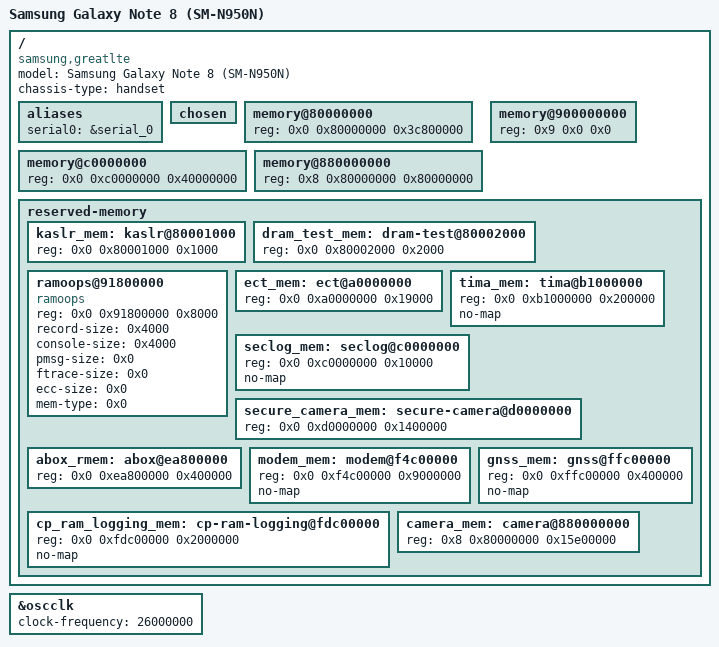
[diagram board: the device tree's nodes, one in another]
// SPDX-License-Identifier: GPL-2.0 OR BSD-3-Clause
/*
 * Samsung Galaxy Note 8 (greatlte, SM-N950N) device tree source
 */

/dts-v1/;

/*
 * Stock: S:arch/arm64/boot/dts/exynos/exynos8895-greatlte-rmem.dtsi:12
 * "/memreserve/ 0xE0000000 0x1900000;", shipped: FDT:3. No user in the
 * stock kernel tree. Owner: the secure-world DRM firmware in cm.bin, which
 * builds a region descriptor {0xe0000000, 0x1900000} for its secure SysMMU
 * page tables and protects it through PPMPU (CM:0x22d2b4-0x22d370, strings
 * CM:0x2306a0 "DRMFW:Invalid page table addr(0x%x)", CM:0x2306c5
 * "DRMFW:PPMPU set fail in SysMMU. ret(%d)"; 4.5, O5 closed).
 * Kept verbatim like stock: memblock_reserve()d, stays in the linear map
 * (A:drivers/of/fdt.c:514-523).
 * It must precede every node, i.e. the #include below: dtc's grammar is
 * "headers memreserves devicetree" (A:scripts/dtc/dtc-parser.y:106-107);
 * same order as A:arch/arm64/boot/dts/airoha/en7581-evb.dts:2-5.
 */
/memreserve/ 0xe0000000 0x1900000;

#include "exynos8895.dtsi"

/ {
	model = "Samsung Galaxy Note 8 (SM-N950N)";	/* FDT:9 "Samsung SM-N950N board based on EXYNOS8895" */
	compatible = "samsung,greatlte", "samsung,exynos8895";
	chassis-type = "handset";

	aliases {
		/*
		 * Stock alias uart0 = &serial_0 (S:arch/arm64/boot/dts/exynos/exynos8895.dtsi:66).
		 * samsung_tty takes the port index from the "serial" alias
		 * (A:drivers/tty/serial/samsung_tty.c:1961), so the debug UART stays
		 * ttySAC0, the name S-Boot passes (" androidboot.sec_atd.tty=/dev/ttySAC0",
		 * SB+0xfacc0). serial_0 itself stays disabled until L1.
		 */
		serial0 = &serial_0;
	};

	/*
	 * S-Boot replaces bootargs wholesale and writes 1-cell (4-byte)
	 * linux,initrd-start/-end = 0x89000000 / 0x89000000 + size into this
	 * node (SB+0xebfb0-0xebfd4 "mov w1, #9; movk w1, #0x5441, lsl #16; cmp w0, w1"
	 * = ATAG_CMDLINE, then setprop "/chosen" "bootargs"; SB+0xec01c-0xec064
	 * "linux,initrd-start"/"-end" as 1-cell values, helper SB+0xebe54 "mov w4, #4").
	 * No bootargs here: it is dead (IK:530; 3.1 step 17). No stdout-path:
	 * S-Boot always passes "console=ram", and of_console_check() ignores
	 * stdout-path whenever console= is on the command line
	 * (A:drivers/of/base.c:2032).
	 */
	chosen {
	};

	/* S:arch/arm64/boot/dts/exynos/exynos8895-greatlte_common.dtsi:27-30, FDT:11126-11129: 968 MiB, ends at the secure hole 0xbc800000 */
	memory@80000000 {
		device_type = "memory";
		reg = <0x0 0x80000000 0x3c800000>;
	};

	/* S:arch/arm64/boot/dts/exynos/exynos8895-greatlte_common.dtsi:32-35, FDT:11131-11134 */
	memory@c0000000 {
		device_type = "memory";
		reg = <0x0 0xc0000000 0x40000000>;
	};

	/* S:arch/arm64/boot/dts/exynos/exynos8895-greatlte_common.dtsi:37-40, FDT:11136-11139 */
	memory@880000000 {
		device_type = "memory";
		reg = <0x8 0x80000000 0x80000000>;
	};

	/*
	 * Filled by S-Boot on 6 GB units: reg = <0x9 0x0 0x80000000>
	 * (SB+0xebff8-0xec00c "cmp w0, #6; b.eq" DRAM==6 test, SB+0xec13c-0xec184
	 * "mov x2, #0x9000000" ... "mov w4, #0xc" setprop).
	 * The node name must be exactly "memory@900000000" (S-Boot looks up that
	 * literal path, SB+0x10e318 "/memory@900000000") and it must carry device_type,
	 * which S-Boot does not add if it has to create the node (SB+0xec18c-0xec198
	 * "mov w1, #0; mov x0, x20; mov x2, x19; bl").
	 * Size 0 is skipped by Linux if S-Boot leaves it (A:drivers/of/fdt.c:1072).
	 * S:arch/arm64/boot/dts/exynos/exynos8895-greatlte_common.dtsi:42-45, FDT:11141-11144.
	 */
	memory@900000000 {
		device_type = "memory";
		reg = <0x9 0x0 0x0>;
	};

	reserved-memory {
		#address-cells = <2>;
		#size-cells = <1>;
		ranges;

		/*
		 * S-Boot KASLR breadcrumb: [0] = 0xcdefcdef, [4] = load - 0x80080000
		 * (SB+0x7cbd8-0x7cc20 "mov x6, #0x1000; movk x6, #0x8000, lsl #16;
		 * mov w3, #0xcdef"). S-Boot names the page "kaslr" (SB+0xa8df4-0xa8e0c
		 * "mov x2, #0x1000; movk x2, #0x8000, lsl #16") and passes
		 * " kaslr_region=0x1000@0x80001000" (SB+0x7c2bc-0x7c2d4 "mov x3, #0x1000;
		 * movk x3, #0x8000, lsl #16"); stock reserves it (S:init/main.c:174-193,
		 * under "#ifdef CONFIG_RELOCATABLE_KERNEL", which stock sets: IK:432).
		 */
		kaslr_mem: kaslr@80001000 {
			reg = <0x0 0x80001000 0x1000>;
		};

		/* Bootloader DRAM-test scratch. S:arch/arm64/boot/dts/exynos/exynos8895-greatlte-rmem.dtsi:20-23, FDT:21-24 */
		dram_test_mem: dram-test@80002000 {
			reg = <0x0 0x80002000 0x2000>;
		};

		/*
		 * Console/panic log readable by the TWRP 3.7.1_12 FBE recovery
		 * kernel. That kernel builds ramoops from exynos-snapshot item
		 * "log_pstore" (S:drivers/trace/exynos-ss.c:570, SZ_32K) at
		 * ess_setup (S-Boot passes 0x91200000: SB+0x7be94 "mov w2, #-0x6ee00000") plus
		 * 2M+2M+2M (MINIMIZED_MODE=y in its IKCONFIG), i.e. 0x91800000,
		 * with record = pmsg = mem/2 (S:drivers/trace/exynos-ss.c:3925-3926).
		 * With the 6.18 zone order (A:fs/pstore/ram.c:787-800) our console
		 * zone lands on its pmsg zone and our dmesg zone on its dump zone.
		 */
		ramoops@91800000 {
			compatible = "ramoops";		/* A:fs/pstore/ram.c:897 */
			reg = <0x0 0x91800000 0x8000>;	/* 0x91200000 + 0x600000; size SZ_32K (S:drivers/trace/exynos-ss.c:570) */
			record-size = <0x4000>;		/* = mem_size/2 (S:drivers/trace/exynos-ss.c:3926); becomes TWRP's dump zone */
			console-size = <0x4000>;	/* = TWRP pmsg_size mem_size/2 (S:drivers/trace/exynos-ss.c:3925) */
			pmsg-size = <0x0>;		/* explicit; A:fs/pstore/ram.c:693 default 0 */
			ftrace-size = <0x0>;		/* explicit; A:fs/pstore/ram.c:692 default 0 */
			ecc-size = <0x0>;		/* explicit; TWRP 4.4 zone reads without ECC */
			mem-type = <0x0>;		/* write-combine, A:fs/pstore/ram_core.c:410,434-435; 1 = noncached also works, 2 (cached) must never be used: dirty lines are lost on reset */
		};

		/* ECT (DVFS/ASV tables). S:arch/arm64/kernel/setup.c:115-136, S:arch/arm64/boot/dts/exynos/exynos8895-greatlte_common.dtsi:22-25, FDT:11121-11124 */
		ect_mem: ect@a0000000 {
			reg = <0x0 0xa0000000 0x19000>;
		};

		/* TIMA log. S:arch/arm64/boot/dts/exynos/exynos8895-greatlte-rmem.dtsi:25-28, FDT:26-29, SB+0xa8d1c-0xa8d30 "mov x2, #0xb1000000; mov x3, #0x200000" */
		tima_mem: tima@b1000000 {
			reg = <0x0 0xb1000000 0x200000>;
			no-map;
		};

		/* Secure-world log buffer. S:arch/arm64/boot/dts/exynos/exynos8895-greatlte-rmem.dtsi:30-33, FDT:31-34, S:drivers/soc/samsung/exynos-seclog.c:230-232 */
		seclog_mem: seclog@c0000000 {
			reg = <0x0 0xc0000000 0x10000>;
			no-map;
		};

		/*
		 * ION secure-camera carveout. Stock kept it reserved and mapped
		 * (S:arch/arm64/boot/dts/exynos/exynos8895-greatlte-rmem.dtsi:41-46 "ion,secure", FDT:42-47; carveout heap,
		 * S:drivers/staging/android/ion/exynos/exynos_ion.c:451-453). No
		 * compatible and no no-map: reserved and mapped exactly as stock.
		 */
		secure_camera_mem: secure-camera@d0000000 {
			reg = <0x0 0xd0000000 0x1400000>;
		};

		/* ABOX debug-dump buffer, IOMMU-mapped by the ABOX driver (L6).
		 * S:arch/arm64/boot/dts/exynos/exynos8895-greatlte-rmem.dtsi:48-51, FDT:49-54, S:sound/soc/samsung/abox/abox_dbg.c:129-136,452-454 */
		abox_rmem: abox@ea800000 {
			reg = <0x0 0xea800000 0x400000>;
		};

		/* CP shared memory. S:arch/arm64/boot/dts/exynos/exynos8895-greatlte-rmem.dtsi:73-76, FDT:72-75 */
		modem_mem: modem@f4c00000 {
			reg = <0x0 0xf4c00000 0x9000000>;
			no-map;
		};

		/* CP RAM logging. S:arch/arm64/boot/dts/exynos/exynos8895-greatlte-rmem.dtsi:78-81, FDT:77-80 */
		cp_ram_logging_mem: cp-ram-logging@fdc00000 {
			reg = <0x0 0xfdc00000 0x2000000>;
			no-map;
		};

		/* GNSS shared memory. S:arch/arm64/boot/dts/exynos/exynos8895-greatlte-rmem.dtsi:83-86, FDT:82-85 */
		gnss_mem: gnss@ffc00000 {
			reg = <0x0 0xffc00000 0x400000>;
			no-map;
		};

		/* ION camera carveout, reserved and mapped as stock
		 * (S:arch/arm64/boot/dts/exynos/exynos8895-greatlte-rmem.dtsi:35-39, FDT:36-40;
		 * S:drivers/staging/android/ion/exynos/exynos_ion.c:451-453) */
		camera_mem: camera@880000000 {
			reg = <0x8 0x80000000 0x15e00000>;
		};
	};
};

/* Board fact (the ACK dtsi leaves it to the board, A:arch/arm64/boot/dts/exynos/exynos8895.dtsi:122-126):
 * 26 MHz OSC. S:arch/arm64/boot/dts/exynos/exynos8895-greatlte_common.dtsi:53-58, FDT:11152-11157 (<0x18cba80>). */
&oscclk {
	clock-frequency = <26000000>;
};
